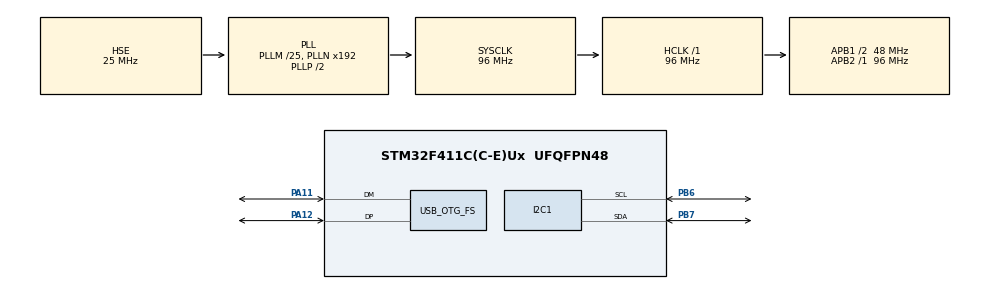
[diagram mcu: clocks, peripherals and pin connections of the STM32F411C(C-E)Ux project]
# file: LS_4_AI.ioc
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Mcu.Family=STM32F4
Mcu.Name=STM32F411C(C-E)Ux
Mcu.Package=UFQFPN48
NVIC.OTG_FS_IRQn=true\:0\:0\:false\:false\:true\:false\:true\:true
NVIC.PriorityGroup=NVIC_PRIORITYGROUP_4
PA11.Mode=Device_Only
PA11.Signal=USB_OTG_FS_DM
PA12.Mode=Device_Only
PA12.Signal=USB_OTG_FS_DP
PB6.Mode=I2C
PB6.Signal=I2C1_SCL
PB7.Mode=I2C
PB7.Signal=I2C1_SDA
PH0\ -\ OSC_IN.Mode=HSE-External-Oscillator
PH0\ -\ OSC_IN.Signal=RCC_OSC_IN
PH1\ -\ OSC_OUT.Mode=HSE-External-Oscillator
PH1\ -\ OSC_OUT.Signal=RCC_OSC_OUT
ProjectManager.HeapSize=0x200
ProjectManager.StackSize=0x400
ProjectManager.TargetToolchain=STM32CubeIDE
RCC.48MHZClocksFreq_Value=48000000
RCC.AHBFreq_Value=96000000
RCC.APB1CLKDivider=RCC_HCLK_DIV2
RCC.APB1Freq_Value=48000000
RCC.APB1TimFreq_Value=96000000
RCC.APB2Freq_Value=96000000
RCC.APB2TimFreq_Value=96000000
RCC.CortexFreq_Value=96000000
RCC.HCLKFreq_Value=96000000
RCC.HSE_VALUE=25000000
RCC.HSI_VALUE=16000000
RCC.LSE_VALUE=32768
RCC.PLLM=25
RCC.SYSCLKFreq_VALUE=96000000
RCC.SYSCLKSource=RCC_SYSCLKSOURCE_PLLCLK
RCC.VCOOutputFreq_Value=192000000
USB_DEVICE.CLASS_NAME_FS=CDC
USB_DEVICE.VirtualMode=Cdc
USB_DEVICE.VirtualModeFS=Cdc_FS
USB_OTG_FS.VirtualMode=Device_Only
VP_USB_DEVICE_VS_USB_DEVICE_CDC_FS.Mode=CDC_FS
board=custom

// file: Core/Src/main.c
/* USER CODE BEGIN Header */
/**
  ******************************************************************************
  * @file           : main.c
  * @brief          : Main program body
  ******************************************************************************
  * @attention
  *
  * Copyright (c) 2026 STMicroelectronics.
  * All rights reserved.
  *
  * This software is licensed under terms that can be found in the LICENSE file
  * in the root directory of this software component.
  * If no LICENSE file comes with this software, it is provided AS-IS.
  *
  ******************************************************************************
  */
/* USER CODE END Header */
#include "main.h"
#include "usb_device.h"

/* USER CODE BEGIN Includes */
#include "usbd_cdc_if.h"
#include "mpu6050.h"
#include <stdio.h>

#include "ei_bridge.h"
#include <string.h>
/* USER CODE END Includes */

I2C_HandleTypeDef hi2c1;

/* USER CODE BEGIN PV */
#define EI_SAMPLE_COUNT 96
#define EI_AXES 3

static float features[EI_SAMPLE_COUNT * EI_AXES];
/* USER CODE END PV */

void SystemClock_Config(void);
static void MX_GPIO_Init(void);
static void MX_I2C1_Init(void);

int main(void)
{

  /* MCU Configuration--------------------------------------------------------*/

  /* Reset of all peripherals, Initializes the Flash interface and the Systick. */
  HAL_Init();

  /* Configure the system clock */
  SystemClock_Config();

  /* Initialize all configured peripherals */
  MX_GPIO_Init();
  MX_I2C1_Init();
  MX_USB_DEVICE_Init();
  HAL_Delay(500);

  /* Initialize MPU6050 */
  if (MPU6050_Init(&hi2c1) != HAL_OK)
  {
      while (1)
      {
          const char error[] = "MPU6050 NOT DETECTED\r\n";

          CDC_Transmit_FS(
              (uint8_t *)error,
              sizeof(error) - 1
          );

          HAL_GPIO_TogglePin(GPIOC, GPIO_PIN_13);
          HAL_Delay(1000);
      }
  }

  /* Sensor detected */
  const char success[] = "MPU6050 DETECTED!\r\n";

  CDC_Transmit_FS(
      (uint8_t *)success,
      sizeof(success) - 1
  );

  /* Sensor initialized successfully */
  HAL_GPIO_WritePin(GPIOC, GPIO_PIN_13, GPIO_PIN_RESET);

  /* Infinite loop */
  /* USER CODE BEGIN WHILE */
  while (1)
  {
      MPU6050_Accel_t accel;

      /* Collect 96 sensor samples */
      for (int i = 0; i < EI_SAMPLE_COUNT; i++)
      {
          if (MPU6050_ReadAccel(&hi2c1, &accel) == HAL_OK)
          {
              /* Convert raw acceleration to milli-g */
              features[i * 3 + 0] =
                  ((float)accel.x * 1000.0f) / 16384.0f;

              features[i * 3 + 1] =
                  ((float)accel.y * 1000.0f) / 16384.0f;

              features[i * 3 + 2] =
                  ((float)accel.z * 1000.0f) / 16384.0f;
          }
          else
          {
              break;
          }

          HAL_Delay(21);
      }

      /* Run Edge Impulse inference through the C-compatible bridge */
      float sitting = 0.0f;
      float standing = 0.0f;
      int status = LS_AI_Classify(features, &sitting, &standing);

      char message[128];

      if (status == 0)
      {
          snprintf(message, sizeof(message),
                   "Sitting: %.3f | Standing: %.3f\r\n",
                   sitting, standing);
      }
      else
      {
          snprintf(message, sizeof(message),
                   "Inference failed: %d\r\n", status);
      }

      CDC_Transmit_FS((uint8_t *)message, strlen(message));

      HAL_Delay(100);
  }
  /* USER CODE END 3 */
}

void SystemClock_Config(void)
{
  RCC_OscInitTypeDef RCC_OscInitStruct = {0};
  RCC_ClkInitTypeDef RCC_ClkInitStruct = {0};

  /** Configure the main internal regulator output voltage
  */
  __HAL_RCC_PWR_CLK_ENABLE();
  __HAL_PWR_VOLTAGESCALING_CONFIG(PWR_REGULATOR_VOLTAGE_SCALE1);

  /** Initializes the RCC Oscillators according to the specified parameters
  * in the RCC_OscInitTypeDef structure.
  */
  RCC_OscInitStruct.OscillatorType = RCC_OSCILLATORTYPE_HSE;
  RCC_OscInitStruct.HSEState = RCC_HSE_ON;
  RCC_OscInitStruct.PLL.PLLState = RCC_PLL_ON;
  RCC_OscInitStruct.PLL.PLLSource = RCC_PLLSOURCE_HSE;
  RCC_OscInitStruct.PLL.PLLM = 25;
  RCC_OscInitStruct.PLL.PLLN = 192;
  RCC_OscInitStruct.PLL.PLLP = RCC_PLLP_DIV2;
  RCC_OscInitStruct.PLL.PLLQ = 4;
  if (HAL_RCC_OscConfig(&RCC_OscInitStruct) != HAL_OK)
  {
    Error_Handler();
  }

  /** Initializes the CPU, AHB and APB buses clocks
  */
  RCC_ClkInitStruct.ClockType = RCC_CLOCKTYPE_HCLK|RCC_CLOCKTYPE_SYSCLK
                              |RCC_CLOCKTYPE_PCLK1|RCC_CLOCKTYPE_PCLK2;
  RCC_ClkInitStruct.SYSCLKSource = RCC_SYSCLKSOURCE_PLLCLK;
  RCC_ClkInitStruct.AHBCLKDivider = RCC_SYSCLK_DIV1;
  RCC_ClkInitStruct.APB1CLKDivider = RCC_HCLK_DIV2;
  RCC_ClkInitStruct.APB2CLKDivider = RCC_HCLK_DIV1;

  if (HAL_RCC_ClockConfig(&RCC_ClkInitStruct, FLASH_LATENCY_3) != HAL_OK)
  {
    Error_Handler();
  }
}

static void MX_I2C1_Init(void)
{

  hi2c1.Instance = I2C1;
  hi2c1.Init.ClockSpeed = 100000;
  hi2c1.Init.DutyCycle = I2C_DUTYCYCLE_2;
  hi2c1.Init.OwnAddress1 = 0;
  hi2c1.Init.AddressingMode = I2C_ADDRESSINGMODE_7BIT;
  hi2c1.Init.DualAddressMode = I2C_DUALADDRESS_DISABLE;
  hi2c1.Init.OwnAddress2 = 0;
  hi2c1.Init.GeneralCallMode = I2C_GENERALCALL_DISABLE;
  hi2c1.Init.NoStretchMode = I2C_NOSTRETCH_DISABLE;
  if (HAL_I2C_Init(&hi2c1) != HAL_OK)
  {
    Error_Handler();
  }

}

static void MX_GPIO_Init(void)
{

  /* GPIO Ports Clock Enable */
    GPIO_InitTypeDef GPIO_InitStruct = {0};

    /* Enable GPIO clocks */
    __HAL_RCC_GPIOH_CLK_ENABLE();
    __HAL_RCC_GPIOA_CLK_ENABLE();
    __HAL_RCC_GPIOB_CLK_ENABLE();
    __HAL_RCC_GPIOC_CLK_ENABLE();

    /* Configure PC13 as output */
    GPIO_InitStruct.Pin = GPIO_PIN_13;
    GPIO_InitStruct.Mode = GPIO_MODE_OUTPUT_PP;
    GPIO_InitStruct.Pull = GPIO_NOPULL;
    GPIO_InitStruct.Speed = GPIO_SPEED_FREQ_LOW;

    HAL_GPIO_Init(GPIOC, &GPIO_InitStruct);

}

void Error_Handler(void)
{
  __disable_irq();
  while (1)
  {
  }
}
